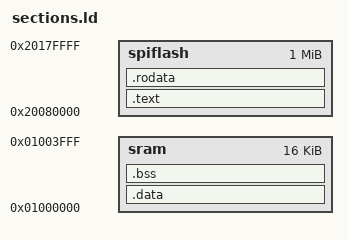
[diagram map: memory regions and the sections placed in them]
OUTPUT_FORMAT("elf32-littleriscv")
ENTRY(_start)

__DYNAMIC = 0;

/* Note: RISCV code is stored in the SPI FLASH */
/* 0x80000 is the offset the bootloader jumps to */
MEMORY {
	sram : ORIGIN = 0x01000000, LENGTH = 0x00004000
	spiflash : ORIGIN = 0x20000000 + 0x80000, LENGTH = 0x00100000
}

SECTIONS
{
	.text :
	{
		_ftext = .;
		*(.text.start)
		*(.text .stub .text.* .gnu.linkonce.t.*)
		_etext = .;
	} > spiflash

	.rodata :
	{
		. = ALIGN(4);
		_frodata = .;
		*(.rodata .rodata.* .gnu.linkonce.r.*)
		*(.rodata1)
		*(.srodata)
		_erodata = .;
	} > spiflash

	.data : AT (ADDR(.rodata) + SIZEOF (.rodata))
	{
		. = ALIGN(4);
		_fdata = .;
		*(.data .data.* .gnu.linkonce.d.*)
		*(.data1)
		_gp = ALIGN(16);
		*(.sdata .sdata.* .gnu.linkonce.s.* .sdata2 .sdata2.*)
		_edata = ALIGN(16); /* Make sure _edata is >= _gp. */
	} > sram

	.bss :
	{
		. = ALIGN(4);
		_fbss = .;
		*(.dynsbss)
		*(.sbss .sbss.* .gnu.linkonce.sb.*)
		*(.scommon)
		*(.dynbss)
		*(.bss .bss.* .gnu.linkonce.b.*)
		*(COMMON)
		. = ALIGN(4);
		_ebss = .;
		_end = .;
	} > sram
}

PROVIDE(_fstack = ORIGIN(sram) + LENGTH(sram) - 4);
